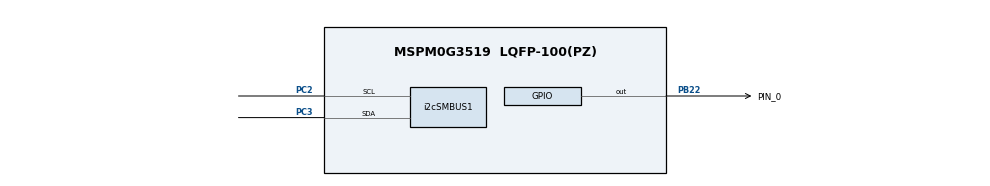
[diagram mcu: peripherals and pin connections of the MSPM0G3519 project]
// @cliArgs --device "MSPM0G351X" --package "LQFP-100(PZ)" --part "Default"
// @v2CliArgs --device "MSPM0G3519" --package "LQFP-100(PZ)"
// @cliArgs --board /ti/boards/LP_MSPM0G3519 --rtos nortos

/**
 * Import the modules used in this configuration.
 */
const ADC12         = scripting.addModule("/ti/driverlib/ADC12", {}, false);
const ADC121        = ADC12.addInstance();
const GPIO          = scripting.addModule("/ti/driverlib/GPIO", {}, false);
const GPIO1         = GPIO.addInstance();
const SYSCTL        = scripting.addModule("/ti/driverlib/SYSCTL");
const TIMER         = scripting.addModule("/ti/driverlib/TIMER", {}, false);
const TIMER1        = TIMER.addInstance();
const i2cSMBUS      = scripting.addModule("/ti/driverlib/i2cSMBUS", {}, false);
const i2cSMBUS1     = i2cSMBUS.addInstance();
const ProjectConfig = scripting.addModule("/ti/project_config/ProjectConfig");

/**
 * Write custom configuration values to the imported modules.
 */
const divider9       = system.clockTree["UDIV"];
divider9.divideValue = 2;

const mux4       = system.clockTree["EXHFMUX"];
mux4.inputSelect = "EXHFMUX_XTAL";

const mux8       = system.clockTree["HSCLKMUX"];
mux8.inputSelect = "HSCLKMUX_SYSPLL2X";

const mux12       = system.clockTree["SYSPLLMUX"];
mux12.inputSelect = "zSYSPLLMUX_HFCLK";

ADC121.$name                             = "SMB_ADC";
ADC121.sampClkDiv                        = "DL_ADC12_CLOCK_DIVIDE_8";
ADC121.repeatMode                        = true;
ADC121.adcMem0_name                      = "SMB_ADC_channel_0";
ADC121.sampleTime0                       = "25 us";
ADC121.sampleTime1                       = "12.5 us";
ADC121.enabledInterrupts                 = ["DL_ADC12_INTERRUPT_MEM0_RESULT_LOADED"];
ADC121.subChanID                         = 3;
ADC121.trigSrc                           = "DL_ADC12_TRIG_SRC_EVENT";
ADC121.peripheral.$assign                = "ADC0";
ADC121.peripheral.adcPin0.$assign        = "PA27";
ADC121.adcPin0Config.hideOutputInversion = scripting.forceWrite(false);

const Board = scripting.addModule("/ti/driverlib/Board", {}, false);

GPIO1.$name                         = "GPIO_LED";
GPIO1.associatedPins[0].$name       = "PIN_0";
GPIO1.associatedPins[0].pin.$assign = "PB22";

SYSCTL.HSCLKSource     = "SYSPLLCLK2X";
SYSCTL.SYSPLL_CLK2XDiv = 3;

TIMER1.$name                       = "ADC_SAMPLE_TIMER";
TIMER1.timerClkSrc                 = "LFCLK";
TIMER1.timerClkDiv                 = 8;
TIMER1.timerMode                   = "PERIODIC";
TIMER1.timerPeriod                 = "10 ms";
TIMER1.timerStartTimer             = true;
TIMER1.event1PublisherChannel      = 3;
TIMER1.event1ControllerInterruptEn = ["ZERO_EVENT"];
TIMER1.peripheral.$assign          = "TIMG0";

i2cSMBUS1.$name                             = "SMB_I2C";
i2cSMBUS1.enableTimeoutA                    = true;
i2cSMBUS1.intGeneric                        = ["TIMEOUT_A"];
i2cSMBUS1.enableControllerPEC               = true;
i2cSMBUS1.timeoutACount                     = 135;
i2cSMBUS1.basicEnableTarget                 = true;
i2cSMBUS1.basicTargetAddress                = 0x1A;
i2cSMBUS1.enableTargetPEC                   = true;
i2cSMBUS1.enableTargetPECACKNext            = true;
i2cSMBUS1.advTargetTXEmptyEn                = true;
i2cSMBUS1.advTargetAckOverride              = true;
i2cSMBUS1.intTarget                         = ["RXFIFO_TRIGGER","START","STOP","TXFIFO_EMPTY"];
i2cSMBUS1.peripheral.$assign                = "I2C2";
i2cSMBUS1.peripheral.sdaPin.$assign         = "PC3";
i2cSMBUS1.peripheral.sclPin.$assign         = "PC2";

ProjectConfig.genLibPMBUS        = true;
